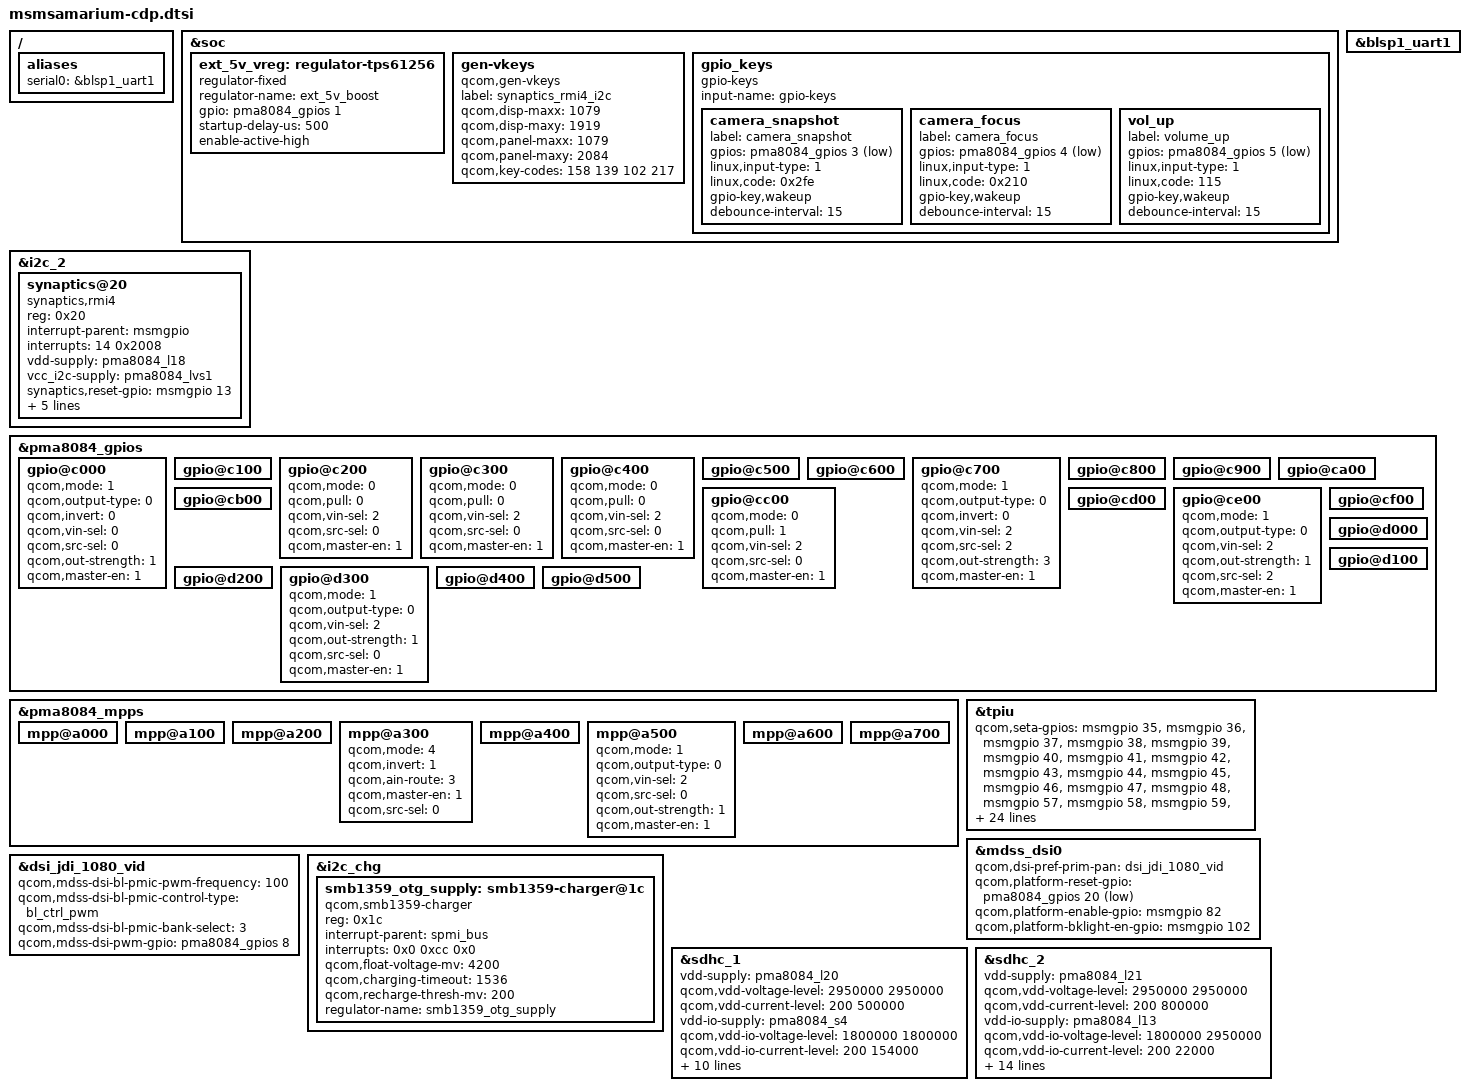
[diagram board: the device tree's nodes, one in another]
/* Copyright (c) 2013, The Linux Foundation. All rights reserved.
 *
 * This program is free software; you can redistribute it and/or modify
 * it under the terms of the GNU General Public License version 2 and
 * only version 2 as published by the Free Software Foundation.
 *
 * This program is distributed in the hope that it will be useful,
 * but WITHOUT ANY WARRANTY; without even the implied warranty of
 * MERCHANTABILITY or FITNESS FOR A PARTICULAR PURPOSE.  See the
 * GNU General Public License for more details.
 */

/ {
	aliases {
		serial0 = &blsp1_uart1;
	};
};

&soc {
	ext_5v_vreg: regulator-tps61256 {
		compatible = "regulator-fixed";
		regulator-name = "ext_5v_boost";
		gpio = <&pma8084_gpios 1 0>;
		startup-delay-us = <500>;
		enable-active-high;
	};

	gen-vkeys {
		compatible = "qcom,gen-vkeys";
		label = "synaptics_rmi4_i2c";
		qcom,disp-maxx = <1079>;
		qcom,disp-maxy = <1919>;
		qcom,panel-maxx = <1079>;
		qcom,panel-maxy = <2084>;
		qcom,key-codes = <158 139 102 217>;
	};

	gpio_keys {
		compatible = "gpio-keys";
		input-name = "gpio-keys";

		camera_snapshot {
			label = "camera_snapshot";
			gpios = <&pma8084_gpios 3 0x1>;
			linux,input-type = <1>;
			linux,code = <0x2fe>;
			gpio-key,wakeup;
			debounce-interval = <15>;
		};

		camera_focus {
			label = "camera_focus";
			gpios = <&pma8084_gpios 4 0x1>;
			linux,input-type = <1>;
			linux,code = <0x210>;
			gpio-key,wakeup;
			debounce-interval = <15>;
		};

		vol_up {
			label = "volume_up";
			gpios = <&pma8084_gpios 5 0x1>;
			linux,input-type = <1>;
			linux,code = <115>;
			gpio-key,wakeup;
			debounce-interval = <15>;
		};
	};
};

&i2c_2 {
	synaptics@20 {
		compatible = "synaptics,rmi4";
		reg = <0x20>;
		interrupt-parent = <&msmgpio>;
		interrupts = <14 0x2008>;
		vdd-supply = <&pma8084_l18>;
		vcc_i2c-supply = <&pma8084_lvs1>;
		synaptics,reset-gpio = <&msmgpio 13 0x00>;
		synaptics,irq-gpio = <&msmgpio 14 0x2008>;
		synaptics,display-coords = <0 0 1079 1919>;
		synaptics,i2c-pull-up;
		synaptics,power-down;
		synaptics,disable-gpios;
	};
};

&blsp1_uart1{
	status = "ok";
};

&pma8084_gpios {
	gpio@c000 { /* GPIO 1 */
		/* 5 V Boost regulator enable */
		qcom,mode = <1>;		/* Digital output */
		qcom,output-type = <0>;		/* CMOS logic */
		qcom,invert = <0>; 		/* Output low initially */
		qcom,vin-sel = <0>; 		/* VPH = battery voltage */
		qcom,src-sel = <0>; 		/* Constant */
		qcom,out-strength = <1>;	/* Low drive strength */
		qcom,master-en = <1>;
	};

	gpio@c100 { /* GPIO 2 */
		/* Unused */
	};

	gpio@c200 { /* GPIO 3 */
		/* Snapshot button */
		qcom,mode = <0>;		/* Digital input */
		qcom,pull = <0>;		/* Pull up 30 uA */
		qcom,vin-sel = <2>;		/* PMA8084 S4 = 1.8 V */
		qcom,src-sel = <0>;		/* Constant */
		qcom,master-en = <1>;
	};

	gpio@c300 { /* GPIO 4 */
		/* Focus button */
		qcom,mode = <0>;		/* Digital input */
		qcom,pull = <0>;		/* Pull up 30 uA */
		qcom,vin-sel = <2>;		/* PMA8084 S4 = 1.8 V */
		qcom,src-sel = <0>;		/* Constant */
		qcom,master-en = <1>;
	};

	gpio@c400 { /* GPIO 5 */
		/* Volume up button */
		qcom,mode = <0>;		/* Digital input */
		qcom,pull = <0>;		/* Pull up 30 uA */
		qcom,vin-sel = <2>;		/* PMA8084 S4 = 1.8 V */
		qcom,src-sel = <0>;		/* Constant */
		qcom,master-en = <1>;
	};

	gpio@c500 { /* GPIO 6 */
		/* SD card write protection switch */
	};

	gpio@c600 { /* GPIO 7 */
		/* Haptics PWM */
	};

	gpio@c700 { /* GPIO 8 */
		/* Backlight PWM */
		qcom,mode = <1>;		/* Digital output */
		qcom,output-type = <0>;		/* CMOS logic */
		qcom,invert = <0>; 		/* Do not invert the output */
		qcom,vin-sel = <2>;		/* PMA8084 S4 = 1.8 V */
		qcom,src-sel = <2>; 		/* Special Function 1 = LPG 4 */
		qcom,out-strength = <3>;	/* High drive strength */
		qcom,master-en = <1>;
	};

	gpio@c800 { /* GPIO 9 */
		/* Unused */
	};

	gpio@c900 { /* GPIO 10 */
		/* NFC clock request */
	};

	gpio@ca00 { /* GPIO 11 */
		/* USB VBUS detect */
	};

	gpio@cb00 { /* GPIO 12 */
		/* NFC power request */
	};

	gpio@cc00 { /* GPIO 13 */
		/* SMB349 STAT */
		qcom,mode = <0>;		/* Digital input */
		qcom,pull = <1>;		/* Pull up 1.5 uA */
		qcom,vin-sel = <2>;		/* PMA8084 S4 = 1.8 V */
		qcom,src-sel = <0>;		/* Constant */
		qcom,master-en = <1>;
	};

	gpio@cd00 { /* GPIO 14 */
		/* UIM3 LDO enable */
	};

	gpio@ce00 { /* GPIO 15 */
		/* Codec clock */
		qcom,mode = <1>;           /* Digital output */
		qcom,output-type = <0>;    /* CMOS */
		qcom,vin-sel = <2>;        /* PMA8084 S4 = 1.8 V */
		qcom,out-strength = <1>;   /* Low */
		qcom,src-sel = <2>;        /* Function 1 - DIVCLK1 */
		qcom,master-en = <1>;
	};

	gpio@cf00 { /* GPIO 16 */
		/* Haptics clock */
	};

	gpio@d000 { /* GPIO 17 */
		/* QPA clock */
	};

	gpio@d100 { /* GPIO 18 */
		/* UIM3 LDO voltage select */
	};

	gpio@d200 { /* GPIO 19 */
		/* BOOST_BYP */
	};

	gpio@d300 { /* GPIO 20 */
		/* Display enable */
		qcom,mode = <1>;		/* Digital output */
		qcom,output-type = <0>;		/* CMOS */
		qcom,vin-sel = <2>;		/* PMA8084 S4 = 1.8 V */
		qcom,out-strength = <1>;	/* Low */
		qcom,src-sel = <0>;		/* Constant */
		qcom,master-en = <1>;
	};

	gpio@d400 { /* GPIO 21 */
		/* BATT_GONE */
	};

	gpio@d500 { /* GPIO 22 */
		/* BATT_REM_ALARM */
	};
};

&pma8084_mpps {
	mpp@a000 { /* MPP 1 */
		/* VREF_PADS */
	};

	mpp@a100 { /* MPP 2 */
		/* Unused */
	};

	mpp@a200 { /* MPP 3 */
		/* VREF_DAC */
	};

	mpp@a300 { /* MPP 4 */
		/* VBATT */
		qcom,mode = <4>; /* AIN input */
		qcom,invert = <1>; /* Enable MPP */
		qcom,ain-route = <3>; /* AMUX 8 */
		qcom,master-en = <1>;
		qcom,src-sel = <0>; /* Function constant */
	};

	mpp@a400 { /* MPP 5 */
		/* Ethernet 3.3 V regulator enable */
	};

	mpp@a500 { /* MPP 6 */
		/* SPI ethernet RST_N */
		qcom,mode = <1>;		/* Digital output */
		qcom,output-type = <0>;		/* CMOS */
		qcom,vin-sel = <2>;		/* PMA8084 S4 = 1.8V > 1.6V */
		qcom,src-sel = <0>;		/* Constant */
		qcom,out-strength = <1>;	/* Low */
		qcom,master-en = <1>;
	};

	mpp@a600 { /* MPP 7 */
		/* SPI ethernet PME */
	};

	mpp@a700 { /* MPP 8 */
		/* SPI ethernet INT_N */
	};
};

/* CoreSight */
&tpiu {
	qcom,seta-gpios = <&msmgpio 35 0>,
			  <&msmgpio 36 0>,
			  <&msmgpio 37 0>,
			  <&msmgpio 38 0>,
			  <&msmgpio 39 0>,
			  <&msmgpio 40 0>,
			  <&msmgpio 41 0>,
			  <&msmgpio 42 0>,
			  <&msmgpio 43 0>,
			  <&msmgpio 44 0>,
			  <&msmgpio 45 0>,
			  <&msmgpio 46 0>,
			  <&msmgpio 47 0>,
			  <&msmgpio 48 0>,
			  <&msmgpio 57 0>,
			  <&msmgpio 58 0>,
			  <&msmgpio 59 0>,
			  <&msmgpio 60 0>;
	qcom,seta-gpios-func = <3 3 3 3 4 3 3 2 2 2 10 10 9 8 10 10 9 8>;
	qcom,seta-gpios-drv =  <7 7 7 7 7 7 7 7 7 7 7 7 7 7 7 7 7 7>;
	qcom,seta-gpios-pull = <0 0 0 0 0 0 0 0 0 0 0 0 0 0 0 0 0 0>;
	qcom,seta-gpios-dir =  <2 2 2 2 2 2 2 2 2 2 2 2 2 2 2 2 2 2>;

	qcom,setb-gpios = <&msmgpio 15 0>,
			  <&msmgpio 16 0>,
			  <&msmgpio 17 0>,
			  <&msmgpio 18 0>,
			  <&msmgpio 19 0>,
			  <&msmgpio 20 0>,
			  <&msmgpio 21 0>,
			  <&msmgpio 22 0>,
			  <&msmgpio 23 0>,
			  <&msmgpio 24 0>,
			  <&msmgpio 25 0>,
			  <&msmgpio 26 0>,
			  <&msmgpio 27 0>,
			  <&msmgpio 28 0>,
			  <&msmgpio 89 0>,
			  <&msmgpio 90 0>,
			  <&msmgpio 91 0>,
			  <&msmgpio 92 0>;
	qcom,setb-gpios-func = <2 2 2 1 2 2 2 2 3 3 3 4 4 2 2 3 3 3>;
	qcom,setb-gpios-drv =  <7 7 7 7 7 7 7 7 7 7 7 7 7 7 7 7 7 7>;
	qcom,setb-gpios-pull = <0 0 0 0 0 0 0 0 0 0 0 0 0 0 0 0 0 0>;
	qcom,setb-gpios-dir =  <2 2 2 2 2 2 2 2 2 2 2 2 2 2 2 2 2 2>;
};

&mdss_dsi0 {
	qcom,dsi-pref-prim-pan = <&dsi_jdi_1080_vid>;
	qcom,platform-reset-gpio = <&pma8084_gpios 20 1>;
	qcom,platform-enable-gpio = <&msmgpio 82 0>;
	qcom,platform-bklight-en-gpio = <&msmgpio 102 0>;
};

&dsi_jdi_1080_vid {
	qcom,mdss-dsi-bl-pmic-pwm-frequency = <100>;
	qcom,mdss-dsi-bl-pmic-control-type = "bl_ctrl_pwm";
	qcom,mdss-dsi-bl-pmic-bank-select = <3>;
	qcom,mdss-dsi-pwm-gpio = <&pma8084_gpios 8 0>;
};

&i2c_chg {
	smb1359_otg_supply: smb1359-charger@1c {
		compatible = "qcom,smb1359-charger";
		reg = <0x1c>;
		interrupt-parent = <&spmi_bus>;
		interrupts = <0x0 0xcc 0x0>;	/* PMA8084 GPIO 13 */
		qcom,float-voltage-mv = <4200>;
		qcom,charging-timeout = <1536>;
		qcom,recharge-thresh-mv = <200>;
		regulator-name = "smb1359_otg_supply";
	};
};

&sdhc_1 {
	vdd-supply = <&pma8084_l20>;
	qcom,vdd-voltage-level = <2950000 2950000>;
	qcom,vdd-current-level = <200 500000>;

	vdd-io-supply = <&pma8084_s4>;
	qcom,vdd-io-voltage-level = <1800000 1800000>;
	qcom,vdd-io-current-level = <200 154000>;
	qcom,vdd-io-always-on;

	qcom,pad-pull-on = <0x0 0x3 0x3 0x1>; /* no-pull, pull-up, pull-up, pull-down */
	qcom,pad-pull-off = <0x0 0x3 0x3 0x1>; /* no-pull, pull-up, pull-up, pull-down */
	qcom,pad-drv-on = <0x7 0x4 0x4>; /* 16mA, 10mA, 10mA */
	qcom,pad-drv-off = <0x0 0x0 0x0>; /* 2mA, 2mA, 2mA */

	qcom,clk-rates = <400000 20000000 25000000 50000000 100000000 192000000 384000000>;
	qcom,bus-speed-mode = "HS400_1p8v", "HS200_1p8v", "DDR_1p8v";
	qcom,nonremovable;

	status = "ok";
};

&sdhc_2 {
	vdd-supply = <&pma8084_l21>;
	qcom,vdd-voltage-level = <2950000 2950000>;
	qcom,vdd-current-level = <200 800000>;

	vdd-io-supply = <&pma8084_l13>;
	qcom,vdd-io-voltage-level = <1800000 2950000>;
	qcom,vdd-io-current-level = <200 22000>;

	qcom,pad-pull-on = <0x0 0x3 0x3>; /* no-pull, pull-up, pull-up */
	qcom,pad-pull-off = <0x0 0x3 0x3>; /* no-pull, pull-up, pull-up */
	qcom,pad-drv-on = <0x7 0x4 0x4>; /* 16mA, 10mA, 10mA */
	qcom,pad-drv-off = <0x0 0x0 0x0>; /* 2mA, 2mA, 2mA */

	qcom,clk-rates = <400000 20000000 25000000 50000000 100000000 200000000>;
	qcom,bus-speed-mode = "SDR12", "SDR25", "SDR50", "DDR50", "SDR104";

	#address-cells = <0>;
	interrupt-parent = <&sdhc_2>;
	interrupts = <0 1 2>;
	#interrupt-cells = <1>;
	interrupt-map-mask = <0xffffffff>;
	interrupt-map = <0 &intc 0 125 0
			1 &intc 0 221 0
			2 &msmgpio 62 0x3>;
	interrupt-names = "hc_irq", "pwr_irq", "status_irq";
	cd-gpios = <&msmgpio 62 0x1>;

	status = "ok";
};
